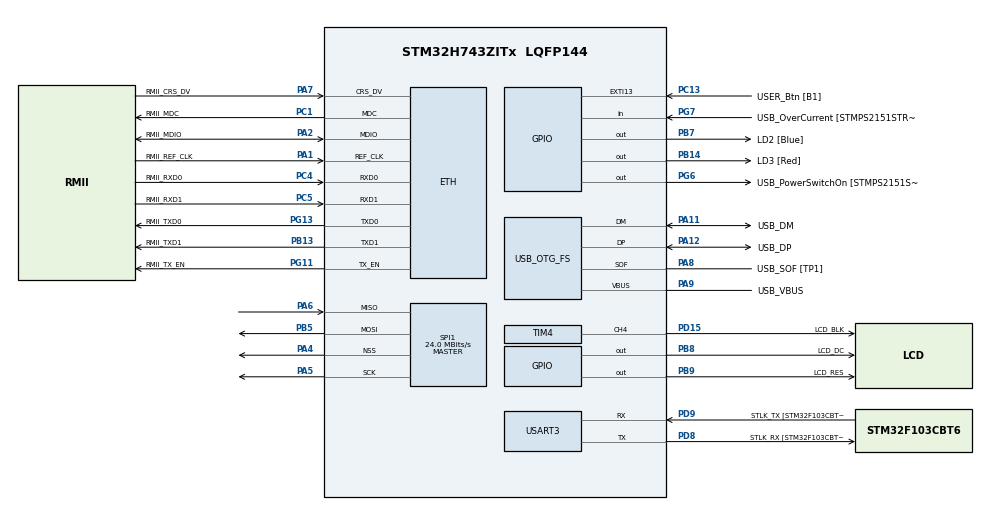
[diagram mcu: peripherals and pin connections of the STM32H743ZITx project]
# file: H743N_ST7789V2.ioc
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Dma.Request0=SPI1_TX
Dma.SPI1_TX.0.Direction=DMA_MEMORY_TO_PERIPH
Dma.SPI1_TX.0.EventEnable=DISABLE
Dma.SPI1_TX.0.FIFOMode=DMA_FIFOMODE_DISABLE
Dma.SPI1_TX.0.Instance=DMA1_Stream0
Dma.SPI1_TX.0.MemDataAlignment=DMA_MDATAALIGN_BYTE
Dma.SPI1_TX.0.MemInc=DMA_MINC_ENABLE
Dma.SPI1_TX.0.Mode=DMA_NORMAL
Dma.SPI1_TX.0.PeriphDataAlignment=DMA_PDATAALIGN_BYTE
Dma.SPI1_TX.0.PeriphInc=DMA_PINC_DISABLE
Dma.SPI1_TX.0.Polarity=HAL_DMAMUX_REQ_GEN_RISING
Dma.SPI1_TX.0.Priority=DMA_PRIORITY_LOW
Dma.SPI1_TX.0.RequestNumber=1
Dma.SPI1_TX.0.SignalID=NONE
Dma.SPI1_TX.0.SyncEnable=DISABLE
Dma.SPI1_TX.0.SyncPolarity=HAL_DMAMUX_SYNC_NO_EVENT
Dma.SPI1_TX.0.SyncRequestNumber=1
Dma.SPI1_TX.0.SyncSignalID=NONE
ETH.MediaInterface=HAL_ETH_RMII_MODE
Mcu.Family=STM32H7
Mcu.Name=STM32H743ZITx
Mcu.Package=LQFP144
NVIC.DMA1_Stream0_IRQn=true\:0\:0\:false\:false\:true\:false\:true\:true
NVIC.PriorityGroup=NVIC_PRIORITYGROUP_4
NVIC.SPI1_IRQn=true\:0\:0\:false\:false\:true\:true\:true\:true
PA1.GPIO_Label=RMII_REF_CLK
PA1.Mode=RMII
PA1.Signal=ETH_REF_CLK
PA10.GPIO_Label=USB_ID
PA10.Signal=USB_OTG_FS_ID
PA11.GPIO_Label=USB_DM
PA11.Mode=Device_Only
PA11.Signal=USB_OTG_FS_DM
PA12.GPIO_Label=USB_DP
PA12.Mode=Device_Only
PA12.Signal=USB_OTG_FS_DP
PA13\ (JTMS/SWDIO).GPIO_Label=TMS
PA13\ (JTMS/SWDIO).Mode=Trace_Asynchronous_SW
PA13\ (JTMS/SWDIO).Signal=DEBUG_JTMS-SWDIO
PA14\ (JTCK/SWCLK).GPIO_Label=TCK
PA14\ (JTCK/SWCLK).Mode=Trace_Asynchronous_SW
PA14\ (JTCK/SWCLK).Signal=DEBUG_JTCK-SWCLK
PA2.GPIO_Label=RMII_MDIO
PA2.Mode=RMII
PA2.Signal=ETH_MDIO
PA4.Mode=NSS_Signal_Hard_Output
PA4.Signal=SPI1_NSS
PA5.Mode=Full_Duplex_Master
PA5.Signal=SPI1_SCK
PA6.Mode=Full_Duplex_Master
PA6.Signal=SPI1_MISO
PA7.GPIO_Label=RMII_CRS_DV
PA7.Mode=RMII
PA7.Signal=ETH_CRS_DV
PA8.GPIO_Label=USB_SOF [TP1]
PA8.Mode=Activate_SOF_FS
PA8.Signal=USB_OTG_FS_SOF
PA9.GPIO_Label=USB_VBUS
PA9.Mode=Activate_VBUS
PA9.Signal=USB_OTG_FS_VBUS
PB13.GPIO_Label=RMII_TXD1
PB13.Mode=RMII
PB13.Signal=ETH_TXD1
PB14.GPIO_Label=LD3 [Red]
PB14.Signal=GPIO_Output
PB3\ (JTDO/TRACESWO).GPIO_Label=SWO
PB3\ (JTDO/TRACESWO).Mode=Trace_Asynchronous_SW
PB3\ (JTDO/TRACESWO).Signal=DEBUG_JTDO-SWO
PB5.Mode=Full_Duplex_Master
PB5.Signal=SPI1_MOSI
PB7.GPIO_Label=LD2 [Blue]
PB7.Signal=GPIO_Output
PB8.GPIO_Label=LCD_DC
PB8.PinState=GPIO_PIN_SET
PB8.Signal=GPIO_Output
PB9.GPIO_Label=LCD_RES
PB9.PinState=GPIO_PIN_SET
PB9.Signal=GPIO_Output
PC1.GPIO_Label=RMII_MDC
PC1.Mode=RMII
PC1.Signal=ETH_MDC
PC13.GPIO_Label=USER_Btn [B1]
PC13.Signal=GPXTI13
PC14-OSC32_IN\ (OSC32_IN).Mode=LSE-External-Oscillator
PC14-OSC32_IN\ (OSC32_IN).Signal=RCC_OSC32_IN
PC15-OSC32_OUT\ (OSC32_OUT).Mode=LSE-External-Oscillator
PC15-OSC32_OUT\ (OSC32_OUT).Signal=RCC_OSC32_OUT
PC4.GPIO_Label=RMII_RXD0
PC4.Mode=RMII
PC4.Signal=ETH_RXD0
PC5.GPIO_Label=RMII_RXD1
PC5.Mode=RMII
PC5.Signal=ETH_RXD1
PD15.GPIO_Label=LCD_BLK
PD15.Signal=S_TIM4_CH4
PD8.GPIO_Label=STLK_RX [STM32F103CBT6_PA3]
PD8.Mode=Asynchronous
PD8.Signal=USART3_TX
PD9.GPIO_Label=STLK_TX [STM32F103CBT6_PA2]
PD9.Mode=Asynchronous
PD9.Signal=USART3_RX
PG11.GPIO_Label=RMII_TX_EN
PG11.Mode=RMII
PG11.Signal=ETH_TX_EN
PG13.GPIO_Label=RMII_TXD0
PG13.Mode=RMII
PG13.Signal=ETH_TXD0
PG6.GPIO_Label=USB_PowerSwitchOn [STMPS2151STR_EN]
PG6.Signal=GPIO_Output
PG7.GPIO_Label=USB_OverCurrent [STMPS2151STR_FAULT]
PG7.Signal=GPIO_Input
PH0-OSC_IN\ (PH0).GPIO_Label=MCO
PH0-OSC_IN\ (PH0).Mode=HSE-External-Clock-Source
PH0-OSC_IN\ (PH0).Signal=RCC_OSC_IN
PH1-OSC_OUT\ (PH1).Signal=RCC_OSC_OUT
ProjectManager.HeapSize=0x200
ProjectManager.StackSize=0x400
ProjectManager.TargetToolchain=STM32CubeIDE
RCC.48MHZClocksFreq_Value=24000000
RCC.ADCFreq_Value=16125000
RCC.AHBFreq_Value=216000000
RCC.APB1CLKDivider=RCC_HCLK_DIV4
RCC.APB1Freq_Value=96000000
RCC.APB1TimFreq_Value=108000000
RCC.APB2CLKDivider=RCC_HCLK_DIV2
RCC.APB2Freq_Value=96000000
RCC.APB2TimFreq_Value=216000000
RCC.APB3Freq_Value=96000000
RCC.APB4Freq_Value=96000000
RCC.CortexFreq_Value=96000000
RCC.DIVM1=1
RCC.DIVN1=24
RCC.DIVQ1=4
RCC.HCLKFreq_Value=96000000
RCC.HSE_VALUE=8000000
RCC.HSI_VALUE=64000000
RCC.PLLM=25
RCC.PLLMUL=RCC_PLL_MUL9
RCC.PLLN=432
RCC.PLLQ=9
RCC.PRESCALERUSB=RCC_USBCLKSOURCE_PLL_DIV1_5
RCC.PWR_Regulator_Voltage_Scale=PWR_REGULATOR_VOLTAGE_SCALE1
RCC.SYSCLKFreq_VALUE=96000000
RCC.SYSCLKSource=RCC_SYSCLKSOURCE_PLLCLK
RCC.SYSCLKSourceVirtual=RCC_SYSCLKSOURCE_PLLCLK
RCC.USBFreq_Value=48000000
RCC.VCOOutputFreq_Value=432000000
SH.S_TIM4_CH4.0=TIM4_CH4,PWM Generation4 CH4
SPI1.CLKPolarity=SPI_POLARITY_HIGH
SPI1.CalculateBaudRate=24.0 MBits/s
SPI1.DataSize=SPI_DATASIZE_8BIT
SPI1.Direction=SPI_DIRECTION_2LINES
SPI1.Mode=SPI_MODE_MASTER
SPI1.VirtualNSS=VM_NSSHARD
SPI1.VirtualType=VM_MASTER
TIM4.Channel-PWM\ Generation4\ CH4=TIM_CHANNEL_4
TIM4.Period=1000-1
TIM4.Prescaler=96-1
TIM4.Pulse-PWM\ Generation4\ CH4=500-1
USART3.VirtualMode-Asynchronous=VM_ASYNC
USB_OTG_FS.VirtualMode=Device_Only
VP_TIM4_VS_ClockSourceINT.Mode=Internal
board=NUCLEO-H743ZI

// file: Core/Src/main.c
/* USER CODE BEGIN Header */
/**
  ******************************************************************************
  * @file           : main.c
  * @brief          : Main program body
  ******************************************************************************
  * @attention
  *
  * Copyright (c) 2023 STMicroelectronics.
  * All rights reserved.
  *
  * This software is licensed under terms that can be found in the LICENSE file
  * in the root directory of this software component.
  * If no LICENSE file comes with this software, it is provided AS-IS.
  *
  ******************************************************************************
  */
/* USER CODE END Header */
#include "main.h"
#include "string.h"

#if defined ( __ICCARM__ ) /*!< IAR Compiler */
#pragma location=0x30000000
ETH_DMADescTypeDef  DMARxDscrTab[ETH_RX_DESC_CNT]; /* Ethernet Rx DMA Descriptors */
#pragma location=0x30000200
ETH_DMADescTypeDef  DMATxDscrTab[ETH_TX_DESC_CNT]; /* Ethernet Tx DMA Descriptors */

#elif defined ( __CC_ARM )  /* MDK ARM Compiler */

__attribute__((at(0x30000000))) ETH_DMADescTypeDef  DMARxDscrTab[ETH_RX_DESC_CNT]; /* Ethernet Rx DMA Descriptors */
__attribute__((at(0x30000200))) ETH_DMADescTypeDef  DMATxDscrTab[ETH_TX_DESC_CNT]; /* Ethernet Tx DMA Descriptors */

#elif defined ( __GNUC__ ) /* GNU Compiler */
ETH_DMADescTypeDef DMARxDscrTab[ETH_RX_DESC_CNT] __attribute__((section(".RxDecripSection"))); /* Ethernet Rx DMA Descriptors */
ETH_DMADescTypeDef DMATxDscrTab[ETH_TX_DESC_CNT] __attribute__((section(".TxDecripSection")));   /* Ethernet Tx DMA Descriptors */

#endif

ETH_TxPacketConfig TxConfig;

ETH_HandleTypeDef heth;

SPI_HandleTypeDef hspi1;
DMA_HandleTypeDef hdma_spi1_tx;

TIM_HandleTypeDef htim4;

UART_HandleTypeDef huart3;

PCD_HandleTypeDef hpcd_USB_OTG_FS;

void SystemClock_Config(void);
static void MX_GPIO_Init(void);
static void MX_DMA_Init(void);
static void MX_USART3_UART_Init(void);
static void MX_USB_OTG_FS_PCD_Init(void);
static void MX_SPI1_Init(void);
static void MX_ETH_Init(void);
static void MX_TIM4_Init(void);

int main(void)
{

  /* MCU Configuration--------------------------------------------------------*/

  /* Reset of all peripherals, Initializes the Flash interface and the Systick. */
  HAL_Init();

  /* Configure the system clock */
  SystemClock_Config();

  /* Initialize all configured peripherals */
  MX_GPIO_Init();
  MX_DMA_Init();
  MX_USART3_UART_Init();
  MX_USB_OTG_FS_PCD_Init();
  MX_SPI1_Init();
  MX_ETH_Init();
  MX_TIM4_Init();
  /* USER CODE BEGIN 2 */

  ST7789_Init();

  ST7789_Test();

  /* USER CODE END 2 */

  /* Infinite loop */
  while (1)
  {

  }
}

void SystemClock_Config(void)
{
  RCC_OscInitTypeDef RCC_OscInitStruct = {0};
  RCC_ClkInitTypeDef RCC_ClkInitStruct = {0};

  /** Supply configuration update enable
  */
  HAL_PWREx_ConfigSupply(PWR_LDO_SUPPLY);

  /** Configure the main internal regulator output voltage
  */
  __HAL_PWR_VOLTAGESCALING_CONFIG(PWR_REGULATOR_VOLTAGE_SCALE1);

  while(!__HAL_PWR_GET_FLAG(PWR_FLAG_VOSRDY)) {}

  /** Initializes the RCC Oscillators according to the specified parameters
  * in the RCC_OscInitTypeDef structure.
  */
  RCC_OscInitStruct.OscillatorType = RCC_OSCILLATORTYPE_HSE;
  RCC_OscInitStruct.HSEState = RCC_HSE_BYPASS;
  RCC_OscInitStruct.PLL.PLLState = RCC_PLL_ON;
  RCC_OscInitStruct.PLL.PLLSource = RCC_PLLSOURCE_HSE;
  RCC_OscInitStruct.PLL.PLLM = 1;
  RCC_OscInitStruct.PLL.PLLN = 24;
  RCC_OscInitStruct.PLL.PLLP = 2;
  RCC_OscInitStruct.PLL.PLLQ = 4;
  RCC_OscInitStruct.PLL.PLLR = 2;
  RCC_OscInitStruct.PLL.PLLRGE = RCC_PLL1VCIRANGE_3;
  RCC_OscInitStruct.PLL.PLLVCOSEL = RCC_PLL1VCOWIDE;
  RCC_OscInitStruct.PLL.PLLFRACN = 0;
  if (HAL_RCC_OscConfig(&RCC_OscInitStruct) != HAL_OK)
  {
    Error_Handler();
  }

  /** Initializes the CPU, AHB and APB buses clocks
  */
  RCC_ClkInitStruct.ClockType = RCC_CLOCKTYPE_HCLK|RCC_CLOCKTYPE_SYSCLK
                              |RCC_CLOCKTYPE_PCLK1|RCC_CLOCKTYPE_PCLK2
                              |RCC_CLOCKTYPE_D3PCLK1|RCC_CLOCKTYPE_D1PCLK1;
  RCC_ClkInitStruct.SYSCLKSource = RCC_SYSCLKSOURCE_PLLCLK;
  RCC_ClkInitStruct.SYSCLKDivider = RCC_SYSCLK_DIV1;
  RCC_ClkInitStruct.AHBCLKDivider = RCC_HCLK_DIV1;
  RCC_ClkInitStruct.APB3CLKDivider = RCC_APB3_DIV1;
  RCC_ClkInitStruct.APB1CLKDivider = RCC_APB1_DIV1;
  RCC_ClkInitStruct.APB2CLKDivider = RCC_APB2_DIV1;
  RCC_ClkInitStruct.APB4CLKDivider = RCC_APB4_DIV1;

  if (HAL_RCC_ClockConfig(&RCC_ClkInitStruct, FLASH_LATENCY_1) != HAL_OK)
  {
    Error_Handler();
  }
}

static void MX_ETH_Init(void)
{

   static uint8_t MACAddr[6];

  heth.Instance = ETH;
  MACAddr[0] = 0x00;
  MACAddr[1] = 0x80;
  MACAddr[2] = 0xE1;
  MACAddr[3] = 0x00;
  MACAddr[4] = 0x00;
  MACAddr[5] = 0x00;
  heth.Init.MACAddr = &MACAddr[0];
  heth.Init.MediaInterface = HAL_ETH_RMII_MODE;
  heth.Init.TxDesc = DMATxDscrTab;
  heth.Init.RxDesc = DMARxDscrTab;
  heth.Init.RxBuffLen = 1524;

  if (HAL_ETH_Init(&heth) != HAL_OK)
  {
    Error_Handler();
  }

  memset(&TxConfig, 0 , sizeof(ETH_TxPacketConfig));
  TxConfig.Attributes = ETH_TX_PACKETS_FEATURES_CSUM | ETH_TX_PACKETS_FEATURES_CRCPAD;
  TxConfig.ChecksumCtrl = ETH_CHECKSUM_IPHDR_PAYLOAD_INSERT_PHDR_CALC;
  TxConfig.CRCPadCtrl = ETH_CRC_PAD_INSERT;

}

static void MX_SPI1_Init(void)
{

  /* SPI1 parameter configuration*/
  hspi1.Instance = SPI1;
  hspi1.Init.Mode = SPI_MODE_MASTER;
  hspi1.Init.Direction = SPI_DIRECTION_2LINES;
  hspi1.Init.DataSize = SPI_DATASIZE_8BIT;
  hspi1.Init.CLKPolarity = SPI_POLARITY_HIGH;
  hspi1.Init.CLKPhase = SPI_PHASE_1EDGE;
  hspi1.Init.NSS = SPI_NSS_HARD_OUTPUT;
  hspi1.Init.BaudRatePrescaler = SPI_BAUDRATEPRESCALER_2;
  hspi1.Init.FirstBit = SPI_FIRSTBIT_MSB;
  hspi1.Init.TIMode = SPI_TIMODE_DISABLE;
  hspi1.Init.CRCCalculation = SPI_CRCCALCULATION_DISABLE;
  hspi1.Init.CRCPolynomial = 0x0;
  hspi1.Init.NSSPMode = SPI_NSS_PULSE_ENABLE;
  hspi1.Init.NSSPolarity = SPI_NSS_POLARITY_LOW;
  hspi1.Init.FifoThreshold = SPI_FIFO_THRESHOLD_01DATA;
  hspi1.Init.TxCRCInitializationPattern = SPI_CRC_INITIALIZATION_ALL_ZERO_PATTERN;
  hspi1.Init.RxCRCInitializationPattern = SPI_CRC_INITIALIZATION_ALL_ZERO_PATTERN;
  hspi1.Init.MasterSSIdleness = SPI_MASTER_SS_IDLENESS_00CYCLE;
  hspi1.Init.MasterInterDataIdleness = SPI_MASTER_INTERDATA_IDLENESS_00CYCLE;
  hspi1.Init.MasterReceiverAutoSusp = SPI_MASTER_RX_AUTOSUSP_DISABLE;
  hspi1.Init.MasterKeepIOState = SPI_MASTER_KEEP_IO_STATE_DISABLE;
  hspi1.Init.IOSwap = SPI_IO_SWAP_DISABLE;
  if (HAL_SPI_Init(&hspi1) != HAL_OK)
  {
    Error_Handler();
  }

}

static void MX_TIM4_Init(void)
{

  TIM_ClockConfigTypeDef sClockSourceConfig = {0};
  TIM_MasterConfigTypeDef sMasterConfig = {0};
  TIM_OC_InitTypeDef sConfigOC = {0};

  htim4.Instance = TIM4;
  htim4.Init.Prescaler = 96-1;
  htim4.Init.CounterMode = TIM_COUNTERMODE_UP;
  htim4.Init.Period = 1000-1;
  htim4.Init.ClockDivision = TIM_CLOCKDIVISION_DIV1;
  htim4.Init.AutoReloadPreload = TIM_AUTORELOAD_PRELOAD_DISABLE;
  if (HAL_TIM_Base_Init(&htim4) != HAL_OK)
  {
    Error_Handler();
  }
  sClockSourceConfig.ClockSource = TIM_CLOCKSOURCE_INTERNAL;
  if (HAL_TIM_ConfigClockSource(&htim4, &sClockSourceConfig) != HAL_OK)
  {
    Error_Handler();
  }
  if (HAL_TIM_PWM_Init(&htim4) != HAL_OK)
  {
    Error_Handler();
  }
  sMasterConfig.MasterOutputTrigger = TIM_TRGO_RESET;
  sMasterConfig.MasterSlaveMode = TIM_MASTERSLAVEMODE_DISABLE;
  if (HAL_TIMEx_MasterConfigSynchronization(&htim4, &sMasterConfig) != HAL_OK)
  {
    Error_Handler();
  }
  sConfigOC.OCMode = TIM_OCMODE_PWM1;
  sConfigOC.Pulse = 500-1;
  sConfigOC.OCPolarity = TIM_OCPOLARITY_HIGH;
  sConfigOC.OCFastMode = TIM_OCFAST_DISABLE;
  if (HAL_TIM_PWM_ConfigChannel(&htim4, &sConfigOC, TIM_CHANNEL_4) != HAL_OK)
  {
    Error_Handler();
  }
  HAL_TIM_MspPostInit(&htim4);

}

static void MX_USART3_UART_Init(void)
{

  huart3.Instance = USART3;
  huart3.Init.BaudRate = 115200;
  huart3.Init.WordLength = UART_WORDLENGTH_8B;
  huart3.Init.StopBits = UART_STOPBITS_1;
  huart3.Init.Parity = UART_PARITY_NONE;
  huart3.Init.Mode = UART_MODE_TX_RX;
  huart3.Init.HwFlowCtl = UART_HWCONTROL_NONE;
  huart3.Init.OverSampling = UART_OVERSAMPLING_16;
  huart3.Init.OneBitSampling = UART_ONE_BIT_SAMPLE_DISABLE;
  huart3.Init.ClockPrescaler = UART_PRESCALER_DIV1;
  huart3.AdvancedInit.AdvFeatureInit = UART_ADVFEATURE_NO_INIT;
  if (HAL_UART_Init(&huart3) != HAL_OK)
  {
    Error_Handler();
  }
  if (HAL_UARTEx_SetTxFifoThreshold(&huart3, UART_TXFIFO_THRESHOLD_1_8) != HAL_OK)
  {
    Error_Handler();
  }
  if (HAL_UARTEx_SetRxFifoThreshold(&huart3, UART_RXFIFO_THRESHOLD_1_8) != HAL_OK)
  {
    Error_Handler();
  }
  if (HAL_UARTEx_DisableFifoMode(&huart3) != HAL_OK)
  {
    Error_Handler();
  }

}

static void MX_USB_OTG_FS_PCD_Init(void)
{

  hpcd_USB_OTG_FS.Instance = USB_OTG_FS;
  hpcd_USB_OTG_FS.Init.dev_endpoints = 9;
  hpcd_USB_OTG_FS.Init.speed = PCD_SPEED_FULL;
  hpcd_USB_OTG_FS.Init.dma_enable = DISABLE;
  hpcd_USB_OTG_FS.Init.phy_itface = PCD_PHY_EMBEDDED;
  hpcd_USB_OTG_FS.Init.Sof_enable = ENABLE;
  hpcd_USB_OTG_FS.Init.low_power_enable = DISABLE;
  hpcd_USB_OTG_FS.Init.lpm_enable = DISABLE;
  hpcd_USB_OTG_FS.Init.battery_charging_enable = ENABLE;
  hpcd_USB_OTG_FS.Init.vbus_sensing_enable = ENABLE;
  hpcd_USB_OTG_FS.Init.use_dedicated_ep1 = DISABLE;
  if (HAL_PCD_Init(&hpcd_USB_OTG_FS) != HAL_OK)
  {
    Error_Handler();
  }

}

static void MX_DMA_Init(void)
{

  /* DMA controller clock enable */
  __HAL_RCC_DMA1_CLK_ENABLE();

  /* DMA interrupt init */
  /* DMA1_Stream0_IRQn interrupt configuration */
  HAL_NVIC_SetPriority(DMA1_Stream0_IRQn, 0, 0);
  HAL_NVIC_EnableIRQ(DMA1_Stream0_IRQn);

}

static void MX_GPIO_Init(void)
{
  GPIO_InitTypeDef GPIO_InitStruct = {0};

  /* GPIO Ports Clock Enable */
  __HAL_RCC_GPIOC_CLK_ENABLE();
  __HAL_RCC_GPIOH_CLK_ENABLE();
  __HAL_RCC_GPIOA_CLK_ENABLE();
  __HAL_RCC_GPIOB_CLK_ENABLE();
  __HAL_RCC_GPIOD_CLK_ENABLE();
  __HAL_RCC_GPIOG_CLK_ENABLE();

  /*Configure GPIO pin Output Level */
  HAL_GPIO_WritePin(GPIOB, LD3_Pin|LD2_Pin, GPIO_PIN_RESET);

  /*Configure GPIO pin Output Level */
  HAL_GPIO_WritePin(USB_PowerSwitchOn_GPIO_Port, USB_PowerSwitchOn_Pin, GPIO_PIN_RESET);

  /*Configure GPIO pin Output Level */
  HAL_GPIO_WritePin(GPIOB, LCD_DC_Pin|LCD_RES_Pin, GPIO_PIN_SET);

  /*Configure GPIO pin : USER_Btn_Pin */
  GPIO_InitStruct.Pin = USER_Btn_Pin;
  GPIO_InitStruct.Mode = GPIO_MODE_IT_RISING;
  GPIO_InitStruct.Pull = GPIO_NOPULL;
  HAL_GPIO_Init(USER_Btn_GPIO_Port, &GPIO_InitStruct);

  /*Configure GPIO pins : LD3_Pin LD2_Pin LCD_DC_Pin LCD_RES_Pin */
  GPIO_InitStruct.Pin = LD3_Pin|LD2_Pin|LCD_DC_Pin|LCD_RES_Pin;
  GPIO_InitStruct.Mode = GPIO_MODE_OUTPUT_PP;
  GPIO_InitStruct.Pull = GPIO_NOPULL;
  GPIO_InitStruct.Speed = GPIO_SPEED_FREQ_LOW;
  HAL_GPIO_Init(GPIOB, &GPIO_InitStruct);

  /*Configure GPIO pin : USB_PowerSwitchOn_Pin */
  GPIO_InitStruct.Pin = USB_PowerSwitchOn_Pin;
  GPIO_InitStruct.Mode = GPIO_MODE_OUTPUT_PP;
  GPIO_InitStruct.Pull = GPIO_NOPULL;
  GPIO_InitStruct.Speed = GPIO_SPEED_FREQ_LOW;
  HAL_GPIO_Init(USB_PowerSwitchOn_GPIO_Port, &GPIO_InitStruct);

  /*Configure GPIO pin : USB_OverCurrent_Pin */
  GPIO_InitStruct.Pin = USB_OverCurrent_Pin;
  GPIO_InitStruct.Mode = GPIO_MODE_INPUT;
  GPIO_InitStruct.Pull = GPIO_NOPULL;
  HAL_GPIO_Init(USB_OverCurrent_GPIO_Port, &GPIO_InitStruct);

}

void Error_Handler(void)
{
  __disable_irq();
  while (1)
  {
  }
}
